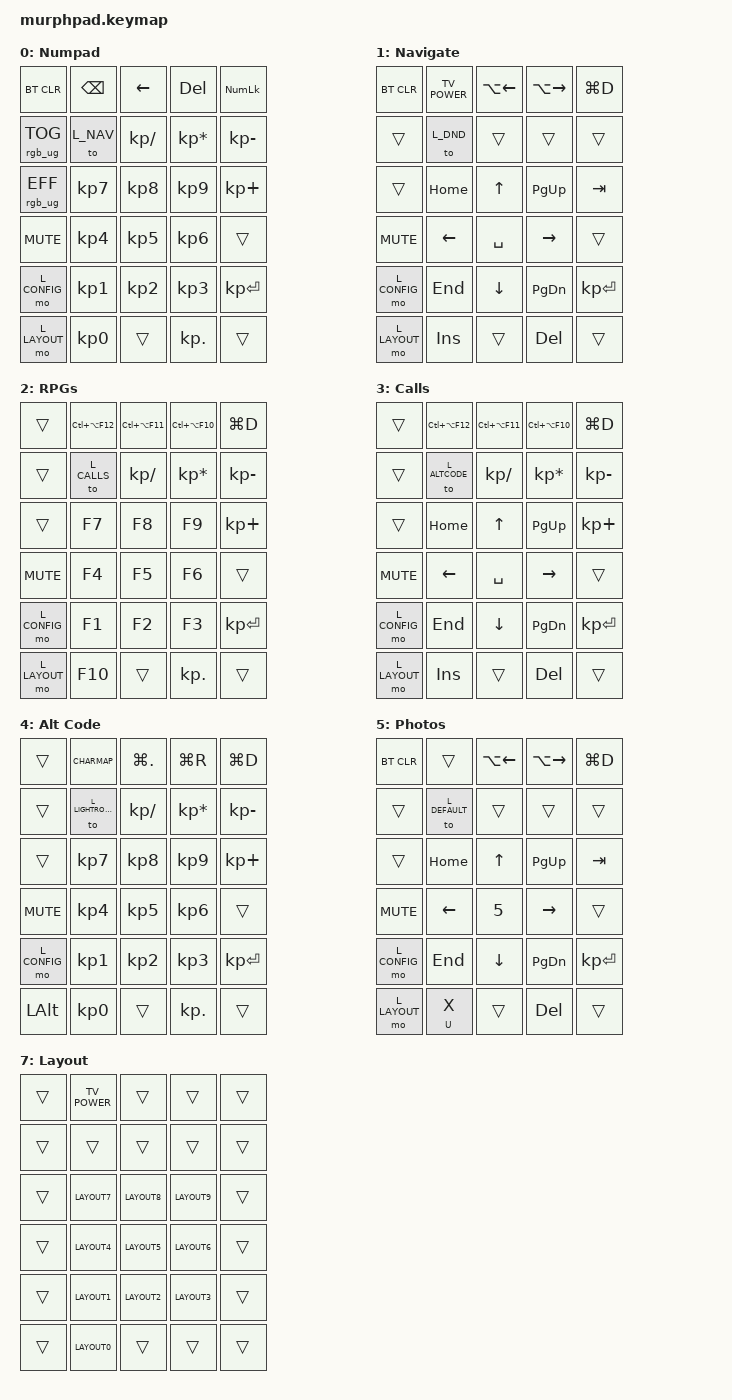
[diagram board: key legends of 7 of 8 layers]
/*
 * Copyright (c) 2021 The ZMK Contributors
 *
 * SPDX-License-Identifier: MIT
 */

#include <behaviors.dtsi>
#include <dt-bindings/zmk/keys.h>
#include <dt-bindings/zmk/bt.h>
#include <dt-bindings/zmk/rgb.h>
#include <dt-bindings/zmk/outputs.h>

#define TIMEOUT 300

#define L_DEFAULT 0
#define L_NAV 1
#define L_DND 2
#define L_CALLS 3
#define L_ALTCODE 4
#define L_LIGHTROOM 5
#define L_CONFIG 6
#define L_LAYOUT 7

&encoder_1 {
    status = "okay";
};
&encoder_2 {
    status = "okay";
};

/ {
    combos {
        compatible = "zmk,combos";
        combo_btclr {
            timeout-ms = <TIMEOUT>;
            key-positions = <1 6>;
            bindings = <&bt BT_CLR>;
        };
        combo_reset {
            timeout-ms = <TIMEOUT>;
            key-positions = <1 3>;
            bindings = <&reset>;
        };
        combo_bootloader {
            timeout-ms = <TIMEOUT>;
            key-positions = <1 2>;
            bindings = <&bootloader>;
        };
        combo_bt_nxt {
            timeout-ms = <TIMEOUT>;
            key-positions = <1 4>;
            bindings = <&bt BT_NXT>;
        };
    };
    
	macros {
		LAYOUT0: LAYOUT0 {
			label = "Layout 0";
			compatible = "zmk,behavior-macro";
			#binding-cells = <0>;
			bindings
				= <&macro_press &kp LCTRL &kp LWIN &kp LALT>
				, <&macro_tap &kp N0>
				, <&macro_release &kp LCTRL &kp LWIN &kp LALT>
				;
		};
		LAYOUT1: LAYOUT1 {
			label = "Layout 1";
			compatible = "zmk,behavior-macro";
			#binding-cells = <0>;
			bindings
				= <&macro_press &kp LCTRL &kp LWIN &kp LALT>
				, <&macro_tap &kp N1>
				, <&macro_release &kp LCTRL &kp LWIN &kp LALT>
				;
		};
		LAYOUT2: LAYOUT2 {
			label = "Layout 2";
			compatible = "zmk,behavior-macro";
			#binding-cells = <0>;
			bindings
				= <&macro_press &kp LCTRL &kp LWIN &kp LALT>
				, <&macro_tap &kp N2>
				, <&macro_release &kp LCTRL &kp LWIN &kp LALT>
				;
		};
		LAYOUT3: LAYOUT3 {
			label = "Layout 3";
			compatible = "zmk,behavior-macro";
			#binding-cells = <0>;
			bindings
				= <&macro_press &kp LCTRL &kp LWIN &kp LALT>
				, <&macro_tap &kp N3>
				, <&macro_release &kp LCTRL &kp LWIN &kp LALT>
				;
		};
		LAYOUT4: LAYOUT4 {
			label = "Layout 4";
			compatible = "zmk,behavior-macro";
			#binding-cells = <0>;
			bindings
				= <&macro_press &kp LCTRL &kp LWIN &kp LALT>
				, <&macro_tap &kp N4>
				, <&macro_release &kp LCTRL &kp LWIN &kp LALT>
				;
		};
		LAYOUT5: LAYOUT5 {
			label = "Layout 5";
			compatible = "zmk,behavior-macro";
			#binding-cells = <0>;
			bindings
				= <&macro_press &kp LCTRL &kp LWIN &kp LALT>
				, <&macro_tap &kp N5>
				, <&macro_release &kp LCTRL &kp LWIN &kp LALT>
				;
		};
		LAYOUT6: LAYOUT6 {
			label = "Layout 6";
			compatible = "zmk,behavior-macro";
			#binding-cells = <0>;
			bindings
				= <&macro_press &kp LCTRL &kp LWIN &kp LALT>
				, <&macro_tap &kp N6>
				, <&macro_release &kp LCTRL &kp LWIN &kp LALT>
				;
		};
		LAYOUT7: LAYOUT7 {
			label = "Layout 7";
			compatible = "zmk,behavior-macro";
			#binding-cells = <0>;
			bindings
				= <&macro_press &kp LCTRL &kp LWIN &kp LALT>
				, <&macro_tap &kp N7>
				, <&macro_release &kp LCTRL &kp LWIN &kp LALT>
				;
		};
		LAYOUT8: LAYOUT8 {
			label = "Layout 8";
			compatible = "zmk,behavior-macro";
			#binding-cells = <0>;
			bindings
				= <&macro_press &kp LCTRL &kp LWIN &kp LALT>
				, <&macro_tap &kp N8>
				, <&macro_release &kp LCTRL &kp LWIN &kp LALT>
				;
		};
		
		LAYOUT9: LAYOUT9 {
			label = "Layout 9";
			compatible = "zmk,behavior-macro";
			#binding-cells = <0>;
			bindings
				= <&macro_press &kp LCTRL &kp LWIN &kp LALT>
				, <&macro_tap &kp N9>
				, <&macro_release &kp LCTRL &kp LWIN &kp LALT>
				;
		};
		
		CHARMAP: CHARMAP {
			label = "character map";
			compatible = "zmk,behavior-macro";
			#binding-cells = <0>;
			bindings
				= <&macro_press &kp LWIN>
				, <&macro_tap &kp R>
				, <&macro_release &kp LWIN>
				, <&macro_wait_time 50>
				, <&macro_tap &kp C>
				, <&macro_tap &kp H>
				, <&macro_tap &kp A>
				, <&macro_tap &kp R>
				, <&macro_tap &kp M>
				, <&macro_tap &kp A>
				, <&macro_tap &kp P>
				, <&macro_tap &kp ENTER>
				;
		};
		
		TV_POWER: TV_POWER {
			label = "TV Power Button";
			compatible = "zmk,behavior-macro";
			#binding-cells = <0>;
			bindings
				= <&macro_press &kp LCTRL &kp LWIN &kp LALT>
				, <&macro_tap &kp END>
				, <&macro_release &kp LCTRL &kp LWIN &kp LALT>
				;
		};
		
	};
	
    sensors {
        compatible = "zmk,keymap-sensors";
        sensors = <&encoder_1 &encoder_2>;
    };


    keymap0: keymap {
        compatible = "zmk,keymap";

        default_layer {
            label = "Numpad";
            bindings = <
                &bt BT_CLR       &kp BSPC      	&kp LEFT        &kp DEL  		&kp KP_NUM   
                &rgb_ug RGB_TOG  &to L_NAV      &kp KP_DIVIDE   &kp KP_MULTIPLY	&kp KP_MINUS    
                &rgb_ug RGB_EFF  &kp KP_N7 	    &kp KP_N8       &kp KP_N9      	&kp KP_PLUS   
                &kp C_MUTE       &kp KP_N4 	    &kp KP_N5       &kp KP_N6      	&trans
                &mo L_CONFIG     &kp KP_N1      &kp KP_N2       &kp KP_N3      	&kp KP_ENTER
                &mo L_LAYOUT     &kp KP_N0 	    &trans          &kp KP_DOT     	&trans
            >;
            sensor-bindings = <&inc_dec_kp C_VOL_DN C_VOL_UP &inc_dec_kp C_AC_SCROLL_UP C_AC_SCROLL_DOWN>;

        }; 
        
        nav_layer {
            label = "Navigate";
            bindings = <
                &bt BT_CLR  	&TV_POWER 		&kp LA(LEFT)    &kp LA(RIGHT)   &kp LG(D)   
                &trans      	&to L_DND   	&trans          &trans          &trans    
                &trans      	&kp HOME		&kp UP          &kp PG_UP       &kp TAB   
                &kp C_MUTE  	&kp LEFT		&kp SPACE       &kp RIGHT       &trans
                &mo L_CONFIG    &kp END 		&kp DOWN        &kp PG_DN       &kp KP_ENTER
                &mo L_LAYOUT  	&kp INS 		&trans          &kp DEL         &trans
            >;
            sensor-bindings = <&inc_dec_kp C_VOL_DN C_VOL_UP &inc_dec_kp UP DOWN>;

        };

        dungeons_and_dragons {
            label = "RPGs";
            bindings = <
                &trans           &kp LC(LA(F12))&kp LC(LA(F11)) &kp LC(LA(F10)) &kp LG(D)   
                &trans           &to L_CALLS   	&kp KP_DIVIDE   &kp KP_MULTIPLY	&kp KP_MINUS    
                &trans           &kp F7      	&kp F8          &kp F9      	&kp KP_PLUS   
                &kp C_MUTE       &kp F4     	&kp F5       	&kp F6      	&trans
                &mo L_CONFIG     &kp F1     	&kp F2       	&kp F3      	&kp KP_ENTER
                &mo L_LAYOUT     &kp F10     	&trans          &kp KP_DOT     	&trans
            >;
            sensor-bindings = <&inc_dec_kp C_VOL_DN C_VOL_UP &inc_dec_kp K_SCROLL_UP K_SCROLL_DOWN>;

        }; 
        
        call_controls {   
            label = "Calls";
            bindings = <
                &trans          &kp LC(LA(F12)) &kp LC(LA(F11)) &kp LC(LA(F10)) &kp LG(D)   
                &trans          &to L_ALTCODE   &kp KP_DIVIDE   &kp KP_MULTIPLY	&kp KP_MINUS    
                &trans      	&kp HOME		&kp UP          &kp PG_UP       &kp KP_PLUS   
                &kp C_MUTE  	&kp LEFT		&kp SPACE       &kp RIGHT       &trans
                &mo L_CONFIG    &kp END 		&kp DOWN        &kp PG_DN       &kp KP_ENTER
                &mo L_LAYOUT  	&kp INS 		&trans          &kp DEL         &trans
            >;
            sensor-bindings = <&inc_dec_kp C_VOL_DN C_VOL_UP &inc_dec_kp LEFT RIGHT>;

        }; 
		
        alt_codes {
            label = "Alt Code";
            bindings = <
                &trans       	 &CHARMAP      	&kp LG(DOT)		&kp LG(R)  		&kp LG(D)   
                &trans  		 &to L_LIGHTROOM  &kp KP_DIVIDE   &kp KP_MULTIPLY	&kp KP_MINUS    
                &trans  		 &kp KP_N7 	    &kp KP_N8       &kp KP_N9      	&kp KP_PLUS   
                &kp C_MUTE       &kp KP_N4 	    &kp KP_N5       &kp KP_N6      	&trans
                &mo L_CONFIG     &kp KP_N1      &kp KP_N2       &kp KP_N3      	&kp KP_ENTER
                &kp LALT         &kp KP_N0 	    &trans          &kp KP_DOT     	&trans
            >;
            sensor-bindings = <&inc_dec_kp C_VOL_DN C_VOL_UP &inc_dec_kp C_AC_SCROLL_UP C_AC_SCROLL_DOWN>;

        }; 
        
        lightroom {
            label = "Photos";
            bindings = <
                &bt BT_CLR  	&trans 			&kp LA(LEFT)    &kp LA(RIGHT)   &kp LG(D)   
                &trans      	&to L_DEFAULT   	&trans          &trans          &trans    
                &trans      	&kp HOME		&kp UP          &kp PG_UP       &kp TAB   
                &kp C_MUTE  	&kp LEFT		&kp 5       	&kp RIGHT       &trans
                &mo L_CONFIG    &kp END 		&kp DOWN        &kp PG_DN       &kp KP_ENTER
                &mo L_LAYOUT  	&mt U X 		&trans          &kp DEL         &trans
            >;
            sensor-bindings = <&inc_dec_kp C_VOL_DN C_VOL_UP &inc_dec_kp C_AC_SCROLL_UP C_AC_SCROLL_DOWN>;

        }; 
        
        fn_layer {
            label = "Config";
            bindings = <
                &trans      	&TV_POWER       &rgb_ug RGB_EFF &rgb_ug RGB_EFR &kp KP_NUM  
                &trans      	&trans          &trans        	&trans          &rgb_ug RGB_BRD     
                &trans      	&trans          &trans        	&trans          &rgb_ug RGB_BRI
                &bt BT_CLR  	&trans          &trans        	&trans          &trans    
                &trans      	&bt BT_SEL 1	&bt BT_SEL 2	&bt BT_SEL 3    &rgb_ug RGB_COLOR_HSB(360,0,100)
                &trans		    &trans          &trans          &trans          &trans           
            >;  
            sensor-bindings = <&inc_dec_kp PG_UP PG_DN &inc_dec_kp C_VOL_DN C_VOL_UP>;
                
        };
        
        screen_setup {
            label = "Layout";
            bindings = <
                &trans     		&TV_POWER  		&trans   		&trans  		&trans   
                &trans     		&trans   		&trans   		&trans  		&trans   
                &trans     		&LAYOUT7 		&LAYOUT8 		&LAYOUT9 		&trans   
                &trans     		&LAYOUT4 		&LAYOUT5 		&LAYOUT6 		&trans
                &trans     		&LAYOUT1 		&LAYOUT2 		&LAYOUT3 		&trans
                &trans     		&LAYOUT0 		&trans   		&trans      	&trans
            >;
            sensor-bindings = <&inc_dec_kp C_VOL_DN C_VOL_UP &inc_dec_kp C_AC_SCROLL_UP C_AC_SCROLL_DOWN>;

        }; 
        
    };
};
